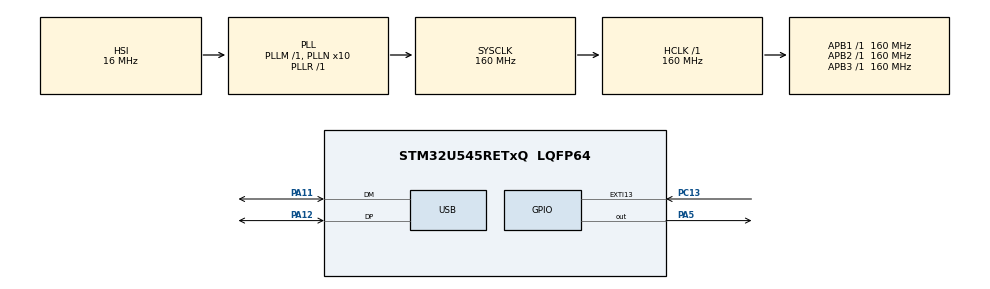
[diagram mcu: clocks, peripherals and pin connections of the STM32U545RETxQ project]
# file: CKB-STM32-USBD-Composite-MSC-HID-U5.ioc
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CORTEX_M33_NS.userName=CORTEX_M33
Mcu.Family=STM32U5
Mcu.Name=STM32U545RETxQ
Mcu.Package=LQFP64
NUCLEO-U545RE-Q.BUTTON=1
NUCLEO-U545RE-Q.LD2=true
NUCLEO-U545RE-Q.VCP=true
NVIC.EXTI13_IRQn=true\:0\:0\:false\:false\:true\:false\:true\:true
NVIC.PriorityGroup=NVIC_PRIORITYGROUP_4
NVIC.USB_IRQn=true\:0\:0\:false\:false\:true\:true\:true\:true
PA11.Mode=Device
PA11.Signal=USB_DM
PA12.Mode=Device
PA12.Signal=USB_DP
PA5.Signal=GPIO_Output
PC13.Signal=GPXTI13
PWR.PowerMode=PWR_SMPS_SUPPLY
ProjectManager.HeapSize=0x200
ProjectManager.StackSize=0x400
ProjectManager.TargetToolchain=STM32CubeIDE
RCC.ADCFreq_Value=16000000
RCC.AHBFreq_Value=160000000
RCC.APB1Freq_Value=160000000
RCC.APB1TimFreq_Value=160000000
RCC.APB2Freq_Value=160000000
RCC.APB2TimFreq_Value=160000000
RCC.APB3Freq_Value=160000000
RCC.CortexFreq_Value=160000000
RCC.DACCLockSelectionVirtual=RCC_DAC1CLKSOURCE_LSI
RCC.DACCLockSelectionVirtualString=RCC_DAC1CLKSOURCE_LSI
RCC.EPOD_VALUE=16000000
RCC.HCLKFreq_Value=160000000
RCC.HSE_VALUE=16000000
RCC.HSI48_VALUE=48000000
RCC.HSI_VALUE=16000000
RCC.LSE_VALUE=32768
RCC.LSIDIV_VALUE=32000
RCC.MSI_VALUE=4000000
RCC.PLL1R=1
RCC.PLLFRACN=0
RCC.PLLN=10
RCC.PLLSourceVirtual=RCC_PLLSOURCE_HSI
RCC.SYSCLKFreq_VALUE=160000000
RCC.SYSCLKSource=RCC_SYSCLKSOURCE_PLLCLK
RCC.USBFreq_Value=48000000
RCC.VCOOutputFreq_Value=160000000
VP_ICACHE_VS_ICACHE.Mode=DirectMappedCache
VP_LPBAMQUEUE_VS_QUEUE.Mode=QUEUEMODE
VP_LPBAM_VS_SIG1.Mode=SmartRun
VP_LPBAM_VS_SIG4.Mode=LPDMA1
VP_MEMORYMAP_VS_MEMORYMAP.Mode=CurAppReg
VP_NUCLEO-U545RE-Q_VS_BSP_COMMON.Mode=COMMON
VP_PWR_VS_LPOM.Mode=PowerOptimisation
VP_PWR_VS_SECSignals.Mode=Security/Privilege
board=NUCLEO-U545RE-Q

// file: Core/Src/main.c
/* USER CODE BEGIN Header */
/**
  ******************************************************************************
  * @file           : main.c
  * @brief          : Main program body
  ******************************************************************************
  * @attention
  *
  * Copyright (c) 2025 STMicroelectronics.
  * All rights reserved.
  *
  * This software is licensed under terms that can be found in the LICENSE file
  * in the root directory of this software component.
  * If no LICENSE file comes with this software, it is provided AS-IS.
  *
  ******************************************************************************
  */
/* USER CODE END Header */
#include "main.h"

PCD_HandleTypeDef hpcd_USB_DRD_FS;
USBD_HandleTypeDef USBD_Device;

uint8_t MSC_EpAdd_Inst[2]={MSC_EPIN_ADDR,MSC_EPOUT_ADDR};
uint8_t HID_EpAdd_Inst   = HID_EPIN_ADDR;
uint8_t hid_InstID= 0;

void SystemClock_Config(void);
static void SystemPower_Config(void);
static void MX_GPIO_Init(void);

int main(void)
{

  /* MCU Configuration--------------------------------------------------------*/

  /* Reset of all peripherals, Initializes the Flash interface and the Systick. */
  HAL_Init();

  /* Configure the System Power */
  SystemPower_Config();

  /* Configure the system clock */
  SystemClock_Config();

   /* Initialize all configured peripherals */
   MX_GPIO_Init();
  /* USER CODE BEGIN 2 */

	/* Initialize USER push-button, will be used to trigger an interrupt each time it's pressed.*/
	BSP_PB_Init(BUTTON_USER, BUTTON_MODE_EXTI);

	/* Init Device Library */
	USBD_Init(&USBD_Device, &Class_Desc, 0);

	/* Add Class MSC */
	USBD_RegisterClassComposite(&USBD_Device ,USBD_MSC_CLASS ,CLASS_TYPE_MSC, MSC_EpAdd_Inst);

	/* Store HID Instance Class ID */
	hid_InstID = USBD_Device.classId;

	/* Add Class MSC */
	USBD_RegisterClassComposite(&USBD_Device,USBD_HID_CLASS,CLASS_TYPE_HID, &HID_EpAdd_Inst);

	/* Add MSC Media interface */
	USBD_CMPSIT_SetClassID(&USBD_Device, CLASS_TYPE_MSC,0);

	/* Add Storage callbacks for MSC Class */
	USBD_MSC_RegisterStorage(&USBD_Device,&USBD_DISK_fops);

	/* Start Device Process */
	USBD_Start(&USBD_Device);

  /* USER CODE END 2 */
  /* Infinite loop */
  while (1)
  {

  }
}

void SystemClock_Config(void)
{
  RCC_OscInitTypeDef RCC_OscInitStruct = {0};
  RCC_ClkInitTypeDef RCC_ClkInitStruct = {0};

  /** Configure the main internal regulator output voltage
  */
  if (HAL_PWREx_ControlVoltageScaling(PWR_REGULATOR_VOLTAGE_SCALE1) != HAL_OK)
  {
    Error_Handler();
  }

  /** Initializes the CPU, AHB and APB buses clocks
  */
  RCC_OscInitStruct.OscillatorType = RCC_OSCILLATORTYPE_HSI48|RCC_OSCILLATORTYPE_HSI;
  RCC_OscInitStruct.HSIState = RCC_HSI_ON;
  RCC_OscInitStruct.HSI48State = RCC_HSI48_ON;
  RCC_OscInitStruct.HSICalibrationValue = RCC_HSICALIBRATION_DEFAULT;
  RCC_OscInitStruct.PLL.PLLState = RCC_PLL_ON;
  RCC_OscInitStruct.PLL.PLLSource = RCC_PLLSOURCE_HSI;
  RCC_OscInitStruct.PLL.PLLMBOOST = RCC_PLLMBOOST_DIV1;
  RCC_OscInitStruct.PLL.PLLM = 1;
  RCC_OscInitStruct.PLL.PLLN = 10;
  RCC_OscInitStruct.PLL.PLLP = 2;
  RCC_OscInitStruct.PLL.PLLQ = 2;
  RCC_OscInitStruct.PLL.PLLR = 1;
  RCC_OscInitStruct.PLL.PLLRGE = RCC_PLLVCIRANGE_1;
  RCC_OscInitStruct.PLL.PLLFRACN = 0;
  if (HAL_RCC_OscConfig(&RCC_OscInitStruct) != HAL_OK)
  {
    Error_Handler();
  }

  /** Initializes the CPU, AHB and APB buses clocks
  */
  RCC_ClkInitStruct.ClockType = RCC_CLOCKTYPE_HCLK|RCC_CLOCKTYPE_SYSCLK
                              |RCC_CLOCKTYPE_PCLK1|RCC_CLOCKTYPE_PCLK2
                              |RCC_CLOCKTYPE_PCLK3;
  RCC_ClkInitStruct.SYSCLKSource = RCC_SYSCLKSOURCE_PLLCLK;
  RCC_ClkInitStruct.AHBCLKDivider = RCC_SYSCLK_DIV1;
  RCC_ClkInitStruct.APB1CLKDivider = RCC_HCLK_DIV1;
  RCC_ClkInitStruct.APB2CLKDivider = RCC_HCLK_DIV1;
  RCC_ClkInitStruct.APB3CLKDivider = RCC_HCLK_DIV1;

  if (HAL_RCC_ClockConfig(&RCC_ClkInitStruct, FLASH_LATENCY_4) != HAL_OK)
  {
    Error_Handler();
  }
}

/**
  * @brief Power Configuration
  * @retval None
  */
static void SystemPower_Config(void)
{

  /*
   * Switch to SMPS regulator instead of LDO
   */
  if (HAL_PWREx_ConfigSupply(PWR_SMPS_SUPPLY) != HAL_OK)
  {
    Error_Handler();
  }
}

static void MX_GPIO_Init(void)
{

  /* GPIO Ports Clock Enable */
  __HAL_RCC_GPIOA_CLK_ENABLE();

}

void Error_Handler(void)
{
  __disable_irq();
  while (1)
  {
  }
}
